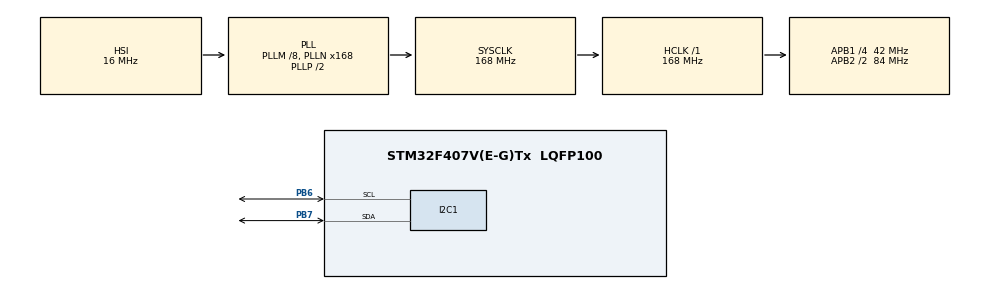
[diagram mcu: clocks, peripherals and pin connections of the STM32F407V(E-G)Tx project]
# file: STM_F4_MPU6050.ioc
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I2C1.I2C_Mode=I2C_Fast
Mcu.Family=STM32F4
Mcu.Name=STM32F407V(E-G)Tx
Mcu.Package=LQFP100
NVIC.I2C1_ER_IRQn=true\:1\:0\:true\:false\:true\:true\:true\:true
NVIC.I2C1_EV_IRQn=true\:1\:0\:true\:false\:true\:true\:true\:true
NVIC.PriorityGroup=NVIC_PRIORITYGROUP_4
PA13.Mode=Trace_Asynchronous_SW
PA13.Signal=SYS_JTMS-SWDIO
PA14.Mode=Trace_Asynchronous_SW
PA14.Signal=SYS_JTCK-SWCLK
PB3.Mode=Trace_Asynchronous_SW
PB3.Signal=SYS_JTDO-SWO
PB6.Mode=I2C
PB6.Signal=I2C1_SCL
PB7.Mode=I2C
PB7.Signal=I2C1_SDA
PH0-OSC_IN.Mode=HSE-External-Oscillator
PH0-OSC_IN.Signal=RCC_OSC_IN
PH1-OSC_OUT.Mode=HSE-External-Oscillator
PH1-OSC_OUT.Signal=RCC_OSC_OUT
ProjectManager.HeapSize=0x200
ProjectManager.StackSize=0x400
ProjectManager.TargetToolchain=STM32CubeIDE
RCC.48MHZClocksFreq_Value=84000000
RCC.AHBFreq_Value=168000000
RCC.APB1CLKDivider=RCC_HCLK_DIV4
RCC.APB1Freq_Value=42000000
RCC.APB1TimFreq_Value=84000000
RCC.APB2CLKDivider=RCC_HCLK_DIV2
RCC.APB2Freq_Value=84000000
RCC.APB2TimFreq_Value=168000000
RCC.CortexFreq_Value=168000000
RCC.HCLKFreq_Value=168000000
RCC.HSE_VALUE=25000000
RCC.HSI_VALUE=16000000
RCC.LSE_VALUE=32768
RCC.PLLM=8
RCC.PLLN=168
RCC.SYSCLKFreq_VALUE=168000000
RCC.SYSCLKSource=RCC_SYSCLKSOURCE_PLLCLK
RCC.VCOOutputFreq_Value=336000000
board=custom

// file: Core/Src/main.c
/* USER CODE BEGIN Header */
/**
  ******************************************************************************
  * @file           : main.c
  * @brief          : Main program body
  ******************************************************************************
  * @attention
  *
  * Copyright (c) 2023 STMicroelectronics.
  * All rights reserved.
  *
  * This software is licensed under terms that can be found in the LICENSE file
  * in the root directory of this software component.
  * If no LICENSE file comes with this software, it is provided AS-IS.
  *
  ******************************************************************************
  */
/* USER CODE END Header */
#include "main.h"

/* USER CODE BEGIN PD */
#define MPU6050_ADDR 0xD0

#define SMPLRT_DIV_REG 0x19
#define DLPF_CONFIG 0x1A
#define GYRO_CONFIG_REG 0x1B
#define ACCEL_CONFIG_REG 0x1C
#define ACCEL_XOUT_H_REG 0x3B
#define TEMP_OUT_H_REG 0x41
#define GYRO_XOUT_H_REG 0x43
#define PWR_MGMT_1_REG 0x6B
#define WHO_AM_I_REG 0x75
/* USER CODE END PD */

I2C_HandleTypeDef hi2c1;

/* USER CODE BEGIN PV */
int16_t Accel_X_RAW = 0;
int16_t Accel_Y_RAW = 0;
int16_t Accel_Z_RAW = 0;

int16_t Gyro_X_RAW = 0;
int16_t Gyro_Y_RAW = 0;
int16_t Gyro_Z_RAW = 0;

float Ax, Ay, Az, Gx, Gy, Gz;
/* USER CODE END PV */

void SystemClock_Config(void);
static void MX_GPIO_Init(void);
static void MX_I2C1_Init(void);

/* USER CODE BEGIN 0 */
void MPU6050_Init (void)
{
	uint8_t check;
	uint8_t Data;

	// Kiểm tra: WHO_AM_I
	HAL_I2C_Mem_Read (&hi2c1, MPU6050_ADDR,WHO_AM_I_REG,1, &check, 1, 1000);

	if (check == 104)  // Nếu hoạt động OK -> 0x68
	{
		// Đánh thức module hoạt động
		Data = 0;
		HAL_I2C_Mem_Write(&hi2c1, MPU6050_ADDR, PWR_MGMT_1_REG, 1,&Data, 1, 1000);

		// Thanh ghi SMPLRT_DIV set Data Rate; 1-8KHz; Đang set 1KHz
		Data = 0x07;
		HAL_I2C_Mem_Write(&hi2c1, MPU6050_ADDR, SMPLRT_DIV_REG, 1, &Data, 1, 1000);

		//Set Digital Low Pass Filter (DLPF)
		// Set Frame Synchronization (FSYNC)
		Data = 0x00;
		HAL_I2C_Mem_Write(&hi2c1, MPU6050_ADDR, DLPF_CONFIG, 1, &Data, 1, 1000);

		// Set ACCEL_CONFIG Register
		// 0=2g; 1=4g; 2=8g; 3=16g
		Data = 0x00; //2g
		HAL_I2C_Mem_Write(&hi2c1, MPU6050_ADDR, ACCEL_CONFIG_REG, 1, &Data, 1, 1000);

		// Set GYRO_CONFIG Register
		// 0=250; 1=500; 2=1000; 3=2000
		Data = 0x00; //250
		HAL_I2C_Mem_Write(&hi2c1, MPU6050_ADDR, GYRO_CONFIG_REG, 1, &Data, 1, 1000);
	}
}

void MPU6050_Read_Accel (void)
{
	uint8_t Rec_Data[6];

	HAL_I2C_Mem_Read (&hi2c1, MPU6050_ADDR, ACCEL_XOUT_H_REG, 1, Rec_Data, 6, 1000);

	Accel_X_RAW = (int16_t)(Rec_Data[0] << 8 | Rec_Data [1]);
	Accel_Y_RAW = (int16_t)(Rec_Data[2] << 8 | Rec_Data [3]);
	Accel_Z_RAW = (int16_t)(Rec_Data[4] << 8 | Rec_Data [5]);

	//Đang set 2g
	//Nếu số khác thì có hệ số chia khác
	Ax = Accel_X_RAW/16384.0;
	Ay = Accel_Y_RAW/16384.0;
	Az = Accel_Z_RAW/16384.0;
}

void MPU6050_Read_Gyro (void)
{
	uint8_t Rec_Data[6];

	HAL_I2C_Mem_Read (&hi2c1, MPU6050_ADDR, GYRO_XOUT_H_REG, 1, Rec_Data, 6, 1000);

	Gyro_X_RAW = (int16_t)(Rec_Data[0] << 8 | Rec_Data [1]);
	Gyro_Y_RAW = (int16_t)(Rec_Data[2] << 8 | Rec_Data [3]);
	Gyro_Z_RAW = (int16_t)(Rec_Data[4] << 8 | Rec_Data [5]);

	//Đang set 250
	//Nếu set số khác thì có hệ số chia khác
	Gx = Gyro_X_RAW/131.0;
	Gy = Gyro_Y_RAW/131.0;
	Gz = Gyro_Z_RAW/131.0;
}
void MPU6050_Read()
{
	MPU6050_Read_Gyro();
	MPU6050_Read_Accel();
}
/* USER CODE END 0 */

int main(void)
{

  /* MCU Configuration--------------------------------------------------------*/

  /* Reset of all peripherals, Initializes the Flash interface and the Systick. */
  HAL_Init();

  /* Configure the system clock */
  SystemClock_Config();

  /* Initialize all configured peripherals */
  MX_GPIO_Init();
  MX_I2C1_Init();
  /* USER CODE BEGIN 2 */
  MPU6050_Init();
  /* USER CODE END 2 */

  /* Infinite loop */
  while (1)
  {

    /* USER CODE BEGIN 3 */
	  MPU6050_Read();
	  HAL_Delay(50);
  }
  /* USER CODE END 3 */
}

void SystemClock_Config(void)
{
  RCC_OscInitTypeDef RCC_OscInitStruct = {0};
  RCC_ClkInitTypeDef RCC_ClkInitStruct = {0};

  /** Configure the main internal regulator output voltage
  */
  __HAL_RCC_PWR_CLK_ENABLE();
  __HAL_PWR_VOLTAGESCALING_CONFIG(PWR_REGULATOR_VOLTAGE_SCALE1);

  /** Initializes the RCC Oscillators according to the specified parameters
  * in the RCC_OscInitTypeDef structure.
  */
  RCC_OscInitStruct.OscillatorType = RCC_OSCILLATORTYPE_HSI;
  RCC_OscInitStruct.HSIState = RCC_HSI_ON;
  RCC_OscInitStruct.HSICalibrationValue = RCC_HSICALIBRATION_DEFAULT;
  RCC_OscInitStruct.PLL.PLLState = RCC_PLL_ON;
  RCC_OscInitStruct.PLL.PLLSource = RCC_PLLSOURCE_HSI;
  RCC_OscInitStruct.PLL.PLLM = 8;
  RCC_OscInitStruct.PLL.PLLN = 168;
  RCC_OscInitStruct.PLL.PLLP = RCC_PLLP_DIV2;
  RCC_OscInitStruct.PLL.PLLQ = 4;
  if (HAL_RCC_OscConfig(&RCC_OscInitStruct) != HAL_OK)
  {
    Error_Handler();
  }

  /** Initializes the CPU, AHB and APB buses clocks
  */
  RCC_ClkInitStruct.ClockType = RCC_CLOCKTYPE_HCLK|RCC_CLOCKTYPE_SYSCLK
                              |RCC_CLOCKTYPE_PCLK1|RCC_CLOCKTYPE_PCLK2;
  RCC_ClkInitStruct.SYSCLKSource = RCC_SYSCLKSOURCE_PLLCLK;
  RCC_ClkInitStruct.AHBCLKDivider = RCC_SYSCLK_DIV1;
  RCC_ClkInitStruct.APB1CLKDivider = RCC_HCLK_DIV4;
  RCC_ClkInitStruct.APB2CLKDivider = RCC_HCLK_DIV2;

  if (HAL_RCC_ClockConfig(&RCC_ClkInitStruct, FLASH_LATENCY_5) != HAL_OK)
  {
    Error_Handler();
  }
}

static void MX_I2C1_Init(void)
{

  hi2c1.Instance = I2C1;
  hi2c1.Init.ClockSpeed = 400000;
  hi2c1.Init.DutyCycle = I2C_DUTYCYCLE_2;
  hi2c1.Init.OwnAddress1 = 0;
  hi2c1.Init.AddressingMode = I2C_ADDRESSINGMODE_7BIT;
  hi2c1.Init.DualAddressMode = I2C_DUALADDRESS_DISABLE;
  hi2c1.Init.OwnAddress2 = 0;
  hi2c1.Init.GeneralCallMode = I2C_GENERALCALL_DISABLE;
  hi2c1.Init.NoStretchMode = I2C_NOSTRETCH_DISABLE;
  if (HAL_I2C_Init(&hi2c1) != HAL_OK)
  {
    Error_Handler();
  }

}

static void MX_GPIO_Init(void)
{

  /* GPIO Ports Clock Enable */
  __HAL_RCC_GPIOH_CLK_ENABLE();
  __HAL_RCC_GPIOA_CLK_ENABLE();
  __HAL_RCC_GPIOB_CLK_ENABLE();

}

void Error_Handler(void)
{
  __disable_irq();
  while (1)
  {
  }
}
